# CONTROL_MODULE register map
Vendor: Texas Instruments
Peripheral module from a debugger description file (folder am437x).
Registers are 32-bit, access per field, no defined reset value unless marked. A register's access mark holds for its fields unless they carry their own. Offsets are as the file gives them; lines under a group give offsets from that group; [hi:lo] are bit positions; {n}, {i} and the like mark numbered series; 'fields as' and 'values as' point back to an identical list; <NAME> marks a mode.

## CONTROL_MODULE (part 1 of 5)
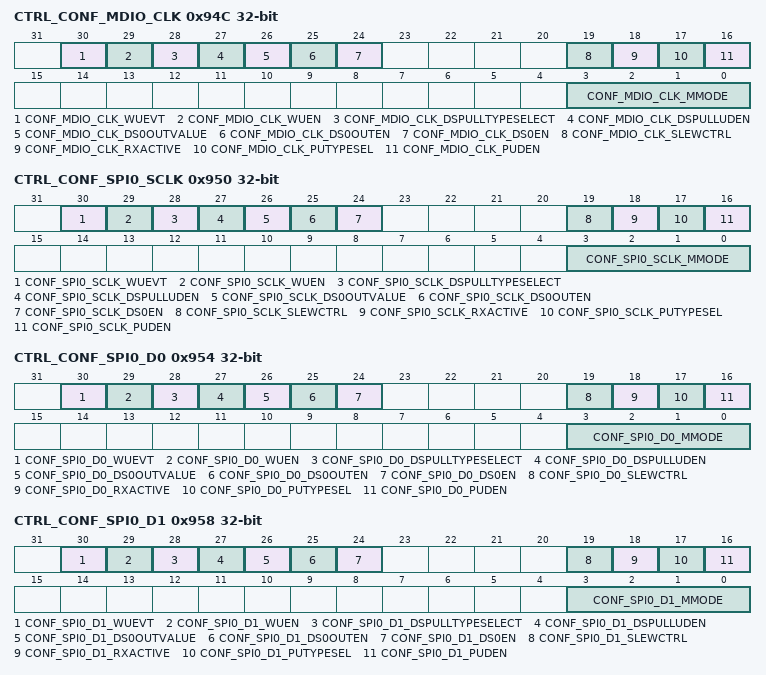
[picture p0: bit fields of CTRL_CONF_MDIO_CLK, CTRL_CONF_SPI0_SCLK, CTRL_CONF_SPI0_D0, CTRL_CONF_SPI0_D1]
0x94C CTRL_CONF_MDIO_CLK
  [30] CONF_MDIO_CLK_WUEVT ro — Wakeup Event [[br]]0 = No event [[br]]1 = Event occurred
  [29] CONF_MDIO_CLK_WUEN rw — Wakeup enable [[br]]0 = disable [[br]]1 = enable
  [28] CONF_MDIO_CLK_DSPULLTYPESELECT rw — DS0 mode Pull-Up/Down selection [[br]]0 = Offmode Pull-Down selected [[br]]1 = Offmode Pull-Up selected
  [27] CONF_MDIO_CLK_DSPULLUDEN rw — DS0 mode Pull-Up/Down enable. [[br]]This is an active low signal. [[br]]1 = Pullup / Pulldown disabled [[br]]0 = Pullup / Pulldown enabled
  [26] CONF_MDIO_CLK_DS0OUTVALUE rw — DS0 mode output value [[br]]0 = Set value at 0 [[br]]1 = Set value at 1
  [25] CONF_MDIO_CLK_DS0OUTEN rw — DS0 mode output enable This is an active low signal [[br]]0 = Output Enable [[br]]1 = Output Disable
  [24] CONF_MDIO_CLK_DS0EN rw — DS0 mode override control [[br]]0: IO state keeps its previous state when DS0 mode is active [[br]]1: IO state is forced to OFF mode value when DS0 mode is active
  [19] CONF_MDIO_CLK_SLEWCTRL rw — Select between Faster or Slower Slew rate [[br]]0 = fast [[br]]1 = slow
  [18] CONF_MDIO_CLK_RXACTIVE rw — Input Enable Value for the PAD [[br]]0 = receiver disabled [[br]]1 = receiver enabled
  [17] CONF_MDIO_CLK_PUTYPESEL rw — Pad Pullup / Pulldown Type Selection [[br]]0 = Pulldown selected [[br]]1 = Pullup selected
  [16] CONF_MDIO_CLK_PUDEN rw — Pad Pullup / Pulldown Enable. [[br]]This is an active low signal [[br]]1 = Pullup / Pulldown disabled [[br]]0 = Pullup / Pulldown enabled
  [3:0] CONF_MDIO_CLK_MMODE rw — Pad Functional Signal Mux Select
0x950 CTRL_CONF_SPI0_SCLK
  [30] CONF_SPI0_SCLK_WUEVT ro — Wakeup Event [[br]]0 = No event [[br]]1 = Event occurred
  [29] CONF_SPI0_SCLK_WUEN rw — Wakeup enable [[br]]0 = disable [[br]]1 = enable
  [28] CONF_SPI0_SCLK_DSPULLTYPESELECT rw — DS0 mode Pull-Up/Down selection [[br]]0 = Offmode Pull-Down selected [[br]]1 = Offmode Pull-Up selected
  [27] CONF_SPI0_SCLK_DSPULLUDEN rw — DS0 mode Pull-Up/Down enable. [[br]]This is an active low signal. [[br]]1 = Pullup / Pulldown disabled [[br]]0 = Pullup / Pulldown enabled
  [26] CONF_SPI0_SCLK_DS0OUTVALUE rw — DS0 mode output value [[br]]0 = Set value at 0 [[br]]1 = Set value at 1
  [25] CONF_SPI0_SCLK_DS0OUTEN rw — DS0 mode output enable This is an active low signal [[br]]0 = Output Enable [[br]]1 = Output Disable
  [24] CONF_SPI0_SCLK_DS0EN rw — DS0 mode override control [[br]]0: IO state keeps its previous state when DS0 mode is active [[br]]1: IO state is forced to OFF mode value when DS0 mode is active
  [19] CONF_SPI0_SCLK_SLEWCTRL rw — Select between Faster or Slower Slew rate [[br]]0 = fast [[br]]1 = slow
  [18] CONF_SPI0_SCLK_RXACTIVE rw — Input Enable Value for the PAD [[br]]0 = receiver disabled [[br]]1 = receiver enabled
  [17] CONF_SPI0_SCLK_PUTYPESEL rw — Pad Pullup / Pulldown Type Selection [[br]]0 = Pulldown selected [[br]]1 = Pullup selected
  [16] CONF_SPI0_SCLK_PUDEN rw — Pad Pullup / Pulldown Enable. [[br]]This is an active low signal [[br]]1 = Pullup / Pulldown disabled [[br]]0 = Pullup / Pulldown enabled
  [3:0] CONF_SPI0_SCLK_MMODE rw — Pad Functional Signal Mux Select
0x954 CTRL_CONF_SPI0_D0
  [30] CONF_SPI0_D0_WUEVT ro — Wakeup Event [[br]]0 = No event [[br]]1 = Event occurred
  [29] CONF_SPI0_D0_WUEN rw — Wakeup enable [[br]]0 = disable [[br]]1 = enable
  [28] CONF_SPI0_D0_DSPULLTYPESELECT rw — DS0 mode Pull-Up/Down selection [[br]]0 = Offmode Pull-Down selected [[br]]1 = Offmode Pull-Up selected
  [27] CONF_SPI0_D0_DSPULLUDEN rw — DS0 mode Pull-Up/Down enable. [[br]]This is an active low signal. [[br]]1 = Pullup / Pulldown disabled [[br]]0 = Pullup / Pulldown enabled
  [26] CONF_SPI0_D0_DS0OUTVALUE rw — DS0 mode output value [[br]]0 = Set value at 0 [[br]]1 = Set value at 1
  [25] CONF_SPI0_D0_DS0OUTEN rw — DS0 mode output enable This is an active low signal [[br]]0 = Output Enable [[br]]1 = Output Disable
  [24] CONF_SPI0_D0_DS0EN rw — DS0 mode override control [[br]]0: IO state keeps its previous state when DS0 mode is active [[br]]1: IO state is forced to OFF mode value when DS0 mode is active
  [19] CONF_SPI0_D0_SLEWCTRL rw — Select between Faster or Slower Slew rate [[br]]0 = fast [[br]]1 = slow
  [18] CONF_SPI0_D0_RXACTIVE rw — Input Enable Value for the PAD [[br]]0 = receiver disabled [[br]]1 = receiver enabled
  [17] CONF_SPI0_D0_PUTYPESEL rw — Pad Pullup / Pulldown Type Selection [[br]]0 = Pulldown selected [[br]]1 = Pullup selected
  [16] CONF_SPI0_D0_PUDEN rw — Pad Pullup / Pulldown Enable. [[br]]This is an active low signal [[br]]1 = Pullup / Pulldown disabled [[br]]0 = Pullup / Pulldown enabled
  [3:0] CONF_SPI0_D0_MMODE rw — Pad Functional Signal Mux Select
0x958 CTRL_CONF_SPI0_D1
  [30] CONF_SPI0_D1_WUEVT ro — Wakeup Event [[br]]0 = No event [[br]]1 = Event occurred
  [29] CONF_SPI0_D1_WUEN rw — Wakeup enable [[br]]0 = disable [[br]]1 = enable
  [28] CONF_SPI0_D1_DSPULLTYPESELECT rw — DS0 mode Pull-Up/Down selection [[br]]0 = Offmode Pull-Down selected [[br]]1 = Offmode Pull-Up selected
  [27] CONF_SPI0_D1_DSPULLUDEN rw — DS0 mode Pull-Up/Down enable. [[br]]This is an active low signal. [[br]]1 = Pullup / Pulldown disabled [[br]]0 = Pullup / Pulldown enabled
  [26] CONF_SPI0_D1_DS0OUTVALUE rw — DS0 mode output value [[br]]0 = Set value at 0 [[br]]1 = Set value at 1
  [25] CONF_SPI0_D1_DS0OUTEN rw — DS0 mode output enable This is an active low signal [[br]]0 = Output Enable [[br]]1 = Output Disable
  [24] CONF_SPI0_D1_DS0EN rw — DS0 mode override control [[br]]0: IO state keeps its previous state when DS0 mode is active [[br]]1: IO state is forced to OFF mode value when DS0 mode is active
  [19] CONF_SPI0_D1_SLEWCTRL rw — Select between Faster or Slower Slew rate [[br]]0 = fast [[br]]1 = slow
  [18] CONF_SPI0_D1_RXACTIVE rw — Input Enable Value for the PAD [[br]]0 = receiver disabled [[br]]1 = receiver enabled
  [17] CONF_SPI0_D1_PUTYPESEL rw — Pad Pullup / Pulldown Type Selection [[br]]0 = Pulldown selected [[br]]1 = Pullup selected
  [16] CONF_SPI0_D1_PUDEN rw — Pad Pullup / Pulldown Enable. [[br]]This is an active low signal [[br]]1 = Pullup / Pulldown disabled [[br]]0 = Pullup / Pulldown enabled
  [3:0] CONF_SPI0_D1_MMODE rw — Pad Functional Signal Mux Select
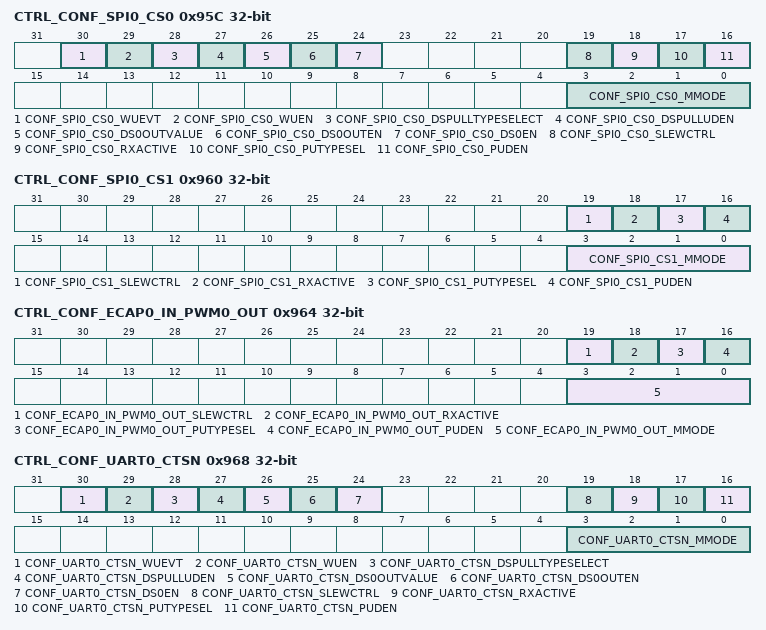
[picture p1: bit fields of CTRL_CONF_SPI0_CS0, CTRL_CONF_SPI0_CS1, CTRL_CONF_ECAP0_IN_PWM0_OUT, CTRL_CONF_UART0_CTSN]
0x95C CTRL_CONF_SPI0_CS0
  [30] CONF_SPI0_CS0_WUEVT ro — Wakeup Event [[br]]0 = No event [[br]]1 = Event occurred
  [29] CONF_SPI0_CS0_WUEN rw — Wakeup enable [[br]]0 = disable [[br]]1 = enable
  [28] CONF_SPI0_CS0_DSPULLTYPESELECT rw — DS0 mode Pull-Up/Down selection [[br]]0 = Offmode Pull-Down selected [[br]]1 = Offmode Pull-Up selected
  [27] CONF_SPI0_CS0_DSPULLUDEN rw — DS0 mode Pull-Up/Down enable. [[br]]This is an active low signal. [[br]]1 = Pullup / Pulldown disabled [[br]]0 = Pullup / Pulldown enabled
  [26] CONF_SPI0_CS0_DS0OUTVALUE rw — DS0 mode output value [[br]]0 = Set value at 0 [[br]]1 = Set value at 1
  [25] CONF_SPI0_CS0_DS0OUTEN rw — DS0 mode output enable This is an active low signal [[br]]0 = Output Enable [[br]]1 = Output Disable
  [24] CONF_SPI0_CS0_DS0EN rw — DS0 mode override control [[br]]0: IO state keeps its previous state when DS0 mode is active [[br]]1: IO state is forced to OFF mode value when DS0 mode is active
  [19] CONF_SPI0_CS0_SLEWCTRL rw — Select between Faster or Slower Slew rate [[br]]0 = fast [[br]]1 = slow
  [18] CONF_SPI0_CS0_RXACTIVE rw — Input Enable Value for the PAD [[br]]0 = receiver disabled [[br]]1 = receiver enabled
  [17] CONF_SPI0_CS0_PUTYPESEL rw — Pad Pullup / Pulldown Type Selection [[br]]0 = Pulldown selected [[br]]1 = Pullup selected
  [16] CONF_SPI0_CS0_PUDEN rw — Pad Pullup / Pulldown Enable. [[br]]This is an active low signal [[br]]1 = Pullup / Pulldown disabled [[br]]0 = Pullup / Pulldown enabled
  [3:0] CONF_SPI0_CS0_MMODE rw — Pad Functional Signal Mux Select
0x960 CTRL_CONF_SPI0_CS1
  [19] CONF_SPI0_CS1_SLEWCTRL rw — Select between Faster or Slower Slew rate [[br]]0 = fast [[br]]1 = slow
  [18] CONF_SPI0_CS1_RXACTIVE rw — Input Enable Value for the PAD [[br]]0 = receiver disabled [[br]]1 = receiver enabled
  [17] CONF_SPI0_CS1_PUTYPESEL rw — Pad Pullup / Pulldown Type Selection [[br]]0 = Pulldown selected [[br]]1 = Pullup selected
  [16] CONF_SPI0_CS1_PUDEN rw — Pad Pullup / Pulldown Enable. [[br]]This is an active low signal [[br]]1 = Pullup / Pulldown disabled [[br]]0 = Pullup / Pulldown enabled
  [3:0] CONF_SPI0_CS1_MMODE rw — Pad Functional Signal Mux Select
0x964 CTRL_CONF_ECAP0_IN_PWM0_OUT
  [19] CONF_ECAP0_IN_PWM0_OUT_SLEWCTRL rw — Select between Faster or Slower Slew rate [[br]]0 = fast [[br]]1 = slow
  [18] CONF_ECAP0_IN_PWM0_OUT_RXACTIVE rw — Input Enable Value for the PAD [[br]]0 = receiver disabled [[br]]1 = receiver enabled
  [17] CONF_ECAP0_IN_PWM0_OUT_PUTYPESEL rw — Pad Pullup / Pulldown Type Selection [[br]]0 = Pulldown selected [[br]]1 = Pullup selected
  [16] CONF_ECAP0_IN_PWM0_OUT_PUDEN rw — Pad Pullup / Pulldown Enable. [[br]]This is an active low signal [[br]]1 = Pullup / Pulldown disabled [[br]]0 = Pullup / Pulldown enabled
  [3:0] CONF_ECAP0_IN_PWM0_OUT_MMODE rw — Pad Functional Signal Mux Select
0x968 CTRL_CONF_UART0_CTSN
  [30] CONF_UART0_CTSN_WUEVT ro — Wakeup Event [[br]]0 = No event [[br]]1 = Event occurred
  [29] CONF_UART0_CTSN_WUEN rw — Wakeup enable [[br]]0 = disable [[br]]1 = enable
  [28] CONF_UART0_CTSN_DSPULLTYPESELECT rw — DS0 mode Pull-Up/Down selection [[br]]0 = Offmode Pull-Down selected [[br]]1 = Offmode Pull-Up selected
  [27] CONF_UART0_CTSN_DSPULLUDEN rw — DS0 mode Pull-Up/Down enable. [[br]]This is an active low signal. [[br]]1 = Pullup / Pulldown disabled [[br]]0 = Pullup / Pulldown enabled
  [26] CONF_UART0_CTSN_DS0OUTVALUE rw — DS0 mode output value [[br]]0 = Set value at 0 [[br]]1 = Set value at 1
  [25] CONF_UART0_CTSN_DS0OUTEN rw — DS0 mode output enable This is an active low signal [[br]]0 = Output Enable [[br]]1 = Output Disable
  [24] CONF_UART0_CTSN_DS0EN rw — DS0 mode override control [[br]]0: IO state keeps its previous state when DS0 mode is active [[br]]1: IO state is forced to OFF mode value when DS0 mode is active
  [19] CONF_UART0_CTSN_SLEWCTRL rw — Select between Faster or Slower Slew rate [[br]]0 = fast [[br]]1 = slow
  [18] CONF_UART0_CTSN_RXACTIVE rw — Input Enable Value for the PAD [[br]]0 = receiver disabled [[br]]1 = receiver enabled
  [17] CONF_UART0_CTSN_PUTYPESEL rw — Pad Pullup / Pulldown Type Selection [[br]]0 = Pulldown selected [[br]]1 = Pullup selected
  [16] CONF_UART0_CTSN_PUDEN rw — Pad Pullup / Pulldown Enable. [[br]]This is an active low signal [[br]]1 = Pullup / Pulldown disabled [[br]]0 = Pullup / Pulldown enabled
  [3:0] CONF_UART0_CTSN_MMODE rw — Pad Functional Signal Mux Select
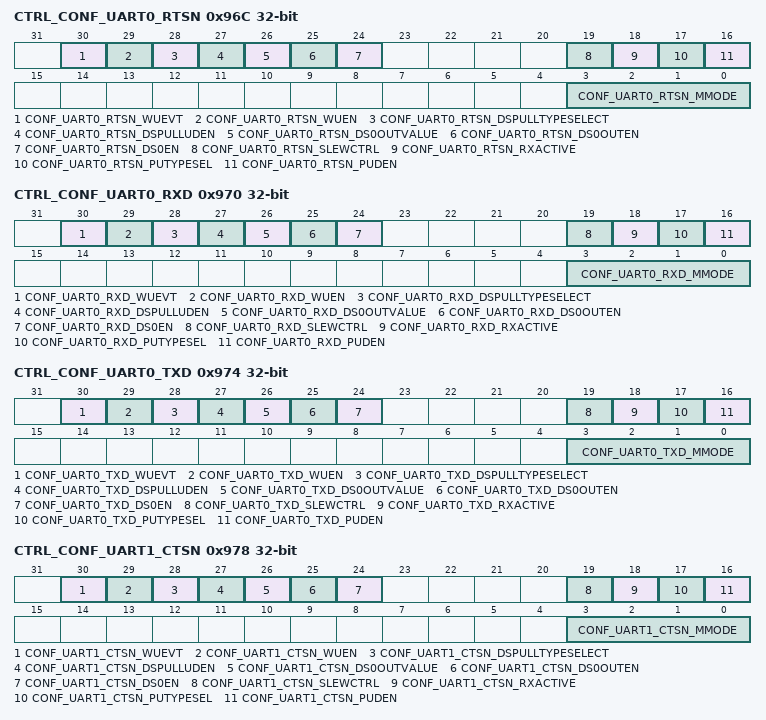
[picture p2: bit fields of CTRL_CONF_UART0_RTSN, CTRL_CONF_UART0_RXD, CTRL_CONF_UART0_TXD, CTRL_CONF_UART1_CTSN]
0x96C CTRL_CONF_UART0_RTSN
  [30] CONF_UART0_RTSN_WUEVT ro — Wakeup Event [[br]]0 = No event [[br]]1 = Event occurred
  [29] CONF_UART0_RTSN_WUEN rw — Wakeup enable [[br]]0 = disable [[br]]1 = enable
  [28] CONF_UART0_RTSN_DSPULLTYPESELECT rw — DS0 mode Pull-Up/Down selection [[br]]0 = Offmode Pull-Down selected [[br]]1 = Offmode Pull-Up selected
  [27] CONF_UART0_RTSN_DSPULLUDEN rw — DS0 mode Pull-Up/Down enable. [[br]]This is an active low signal. [[br]]1 = Pullup / Pulldown disabled [[br]]0 = Pullup / Pulldown enabled
  [26] CONF_UART0_RTSN_DS0OUTVALUE rw — DS0 mode output value [[br]]0 = Set value at 0 [[br]]1 = Set value at 1
  [25] CONF_UART0_RTSN_DS0OUTEN rw — DS0 mode output enable This is an active low signal [[br]]0 = Output Enable [[br]]1 = Output Disable
  [24] CONF_UART0_RTSN_DS0EN rw — DS0 mode override control [[br]]0: IO state keeps its previous state when DS0 mode is active [[br]]1: IO state is forced to OFF mode value when DS0 mode is active
  [19] CONF_UART0_RTSN_SLEWCTRL rw — Select between Faster or Slower Slew rate [[br]]0 = fast [[br]]1 = slow
  [18] CONF_UART0_RTSN_RXACTIVE rw — Input Enable Value for the PAD [[br]]0 = receiver disabled [[br]]1 = receiver enabled
  [17] CONF_UART0_RTSN_PUTYPESEL rw — Pad Pullup / Pulldown Type Selection [[br]]0 = Pulldown selected [[br]]1 = Pullup selected
  [16] CONF_UART0_RTSN_PUDEN rw — Pad Pullup / Pulldown Enable. [[br]]This is an active low signal [[br]]1 = Pullup / Pulldown disabled [[br]]0 = Pullup / Pulldown enabled
  [3:0] CONF_UART0_RTSN_MMODE rw — Pad Functional Signal Mux Select
0x970 CTRL_CONF_UART0_RXD
  [30] CONF_UART0_RXD_WUEVT ro — Wakeup Event [[br]]0 = No event [[br]]1 = Event occurred
  [29] CONF_UART0_RXD_WUEN rw — Wakeup enable [[br]]0 = disable [[br]]1 = enable
  [28] CONF_UART0_RXD_DSPULLTYPESELECT rw — DS0 mode Pull-Up/Down selection [[br]]0 = Offmode Pull-Down selected [[br]]1 = Offmode Pull-Up selected
  [27] CONF_UART0_RXD_DSPULLUDEN rw — DS0 mode Pull-Up/Down enable. [[br]]This is an active low signal. [[br]]1 = Pullup / Pulldown disabled [[br]]0 = Pullup / Pulldown enabled
  [26] CONF_UART0_RXD_DS0OUTVALUE rw — DS0 mode output value [[br]]0 = Set value at 0 [[br]]1 = Set value at 1
  [25] CONF_UART0_RXD_DS0OUTEN rw — DS0 mode output enable This is an active low signal [[br]]0 = Output Enable [[br]]1 = Output Disable
  [24] CONF_UART0_RXD_DS0EN rw — DS0 mode override control [[br]]0: IO state keeps its previous state when DS0 mode is active [[br]]1: IO state is forced to OFF mode value when DS0 mode is active
  [19] CONF_UART0_RXD_SLEWCTRL rw — Select between Faster or Slower Slew rate [[br]]0 = fast [[br]]1 = slow
  [18] CONF_UART0_RXD_RXACTIVE rw — Input Enable Value for the PAD [[br]]0 = receiver disabled [[br]]1 = receiver enabled
  [17] CONF_UART0_RXD_PUTYPESEL rw — Pad Pullup / Pulldown Type Selection [[br]]0 = Pulldown selected [[br]]1 = Pullup selected
  [16] CONF_UART0_RXD_PUDEN rw — Pad Pullup / Pulldown Enable. [[br]]This is an active low signal [[br]]1 = Pullup / Pulldown disabled [[br]]0 = Pullup / Pulldown enabled
  [3:0] CONF_UART0_RXD_MMODE rw — Pad Functional Signal Mux Select
0x974 CTRL_CONF_UART0_TXD
  [30] CONF_UART0_TXD_WUEVT ro — Wakeup Event [[br]]0 = No event [[br]]1 = Event occurred
  [29] CONF_UART0_TXD_WUEN rw — Wakeup enable [[br]]0 = disable [[br]]1 = enable
  [28] CONF_UART0_TXD_DSPULLTYPESELECT rw — DS0 mode Pull-Up/Down selection [[br]]0 = Offmode Pull-Down selected [[br]]1 = Offmode Pull-Up selected
  [27] CONF_UART0_TXD_DSPULLUDEN rw — DS0 mode Pull-Up/Down enable. [[br]]This is an active low signal. [[br]]1 = Pullup / Pulldown disabled [[br]]0 = Pullup / Pulldown enabled
  [26] CONF_UART0_TXD_DS0OUTVALUE rw — DS0 mode output value [[br]]0 = Set value at 0 [[br]]1 = Set value at 1
  [25] CONF_UART0_TXD_DS0OUTEN rw — DS0 mode output enable This is an active low signal [[br]]0 = Output Enable [[br]]1 = Output Disable
  [24] CONF_UART0_TXD_DS0EN rw — DS0 mode override control [[br]]0: IO state keeps its previous state when DS0 mode is active [[br]]1: IO state is forced to OFF mode value when DS0 mode is active
  [19] CONF_UART0_TXD_SLEWCTRL rw — Select between Faster or Slower Slew rate [[br]]0 = fast [[br]]1 = slow
  [18] CONF_UART0_TXD_RXACTIVE rw — Input Enable Value for the PAD [[br]]0 = receiver disabled [[br]]1 = receiver enabled
  [17] CONF_UART0_TXD_PUTYPESEL rw — Pad Pullup / Pulldown Type Selection [[br]]0 = Pulldown selected [[br]]1 = Pullup selected
  [16] CONF_UART0_TXD_PUDEN rw — Pad Pullup / Pulldown Enable. [[br]]This is an active low signal [[br]]1 = Pullup / Pulldown disabled [[br]]0 = Pullup / Pulldown enabled
  [3:0] CONF_UART0_TXD_MMODE rw — Pad Functional Signal Mux Select
0x978 CTRL_CONF_UART1_CTSN
  [30] CONF_UART1_CTSN_WUEVT ro — Wakeup Event [[br]]0 = No event [[br]]1 = Event occurred
  [29] CONF_UART1_CTSN_WUEN rw — Wakeup enable [[br]]0 = disable [[br]]1 = enable
  [28] CONF_UART1_CTSN_DSPULLTYPESELECT rw — DS0 mode Pull-Up/Down selection [[br]]0 = Offmode Pull-Down selected [[br]]1 = Offmode Pull-Up selected
  [27] CONF_UART1_CTSN_DSPULLUDEN rw — DS0 mode Pull-Up/Down enable. [[br]]This is an active low signal. [[br]]1 = Pullup / Pulldown disabled [[br]]0 = Pullup / Pulldown enabled
  [26] CONF_UART1_CTSN_DS0OUTVALUE rw — DS0 mode output value [[br]]0 = Set value at 0 [[br]]1 = Set value at 1
  [25] CONF_UART1_CTSN_DS0OUTEN rw — DS0 mode output enable This is an active low signal [[br]]0 = Output Enable [[br]]1 = Output Disable
  [24] CONF_UART1_CTSN_DS0EN rw — DS0 mode override control [[br]]0: IO state keeps its previous state when DS0 mode is active [[br]]1: IO state is forced to OFF mode value when DS0 mode is active
  [19] CONF_UART1_CTSN_SLEWCTRL rw — Select between Faster or Slower Slew rate [[br]]0 = fast [[br]]1 = slow
  [18] CONF_UART1_CTSN_RXACTIVE rw — Input Enable Value for the PAD [[br]]0 = receiver disabled [[br]]1 = receiver enabled
  [17] CONF_UART1_CTSN_PUTYPESEL rw — Pad Pullup / Pulldown Type Selection [[br]]0 = Pulldown selected [[br]]1 = Pullup selected
  [16] CONF_UART1_CTSN_PUDEN rw — Pad Pullup / Pulldown Enable. [[br]]This is an active low signal [[br]]1 = Pullup / Pulldown disabled [[br]]0 = Pullup / Pulldown enabled
  [3:0] CONF_UART1_CTSN_MMODE rw — Pad Functional Signal Mux Select
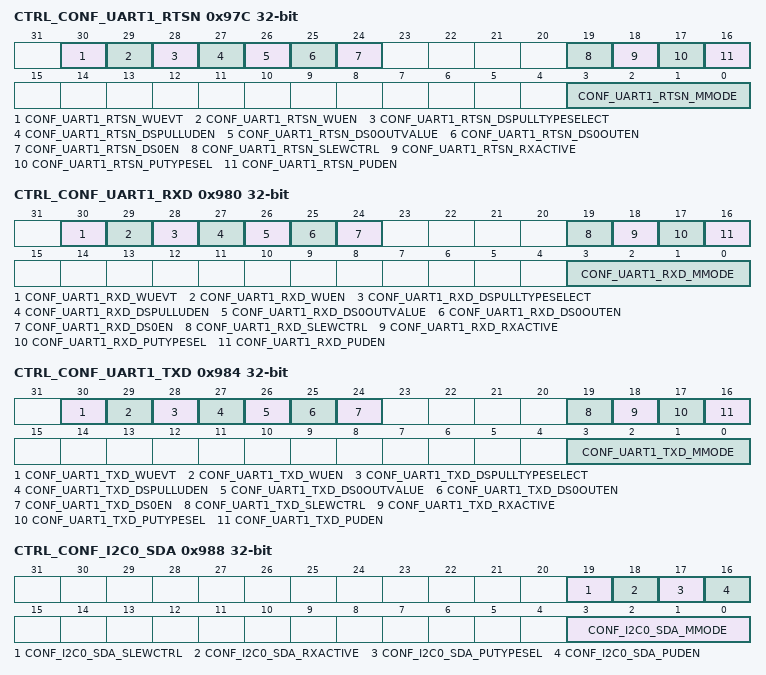
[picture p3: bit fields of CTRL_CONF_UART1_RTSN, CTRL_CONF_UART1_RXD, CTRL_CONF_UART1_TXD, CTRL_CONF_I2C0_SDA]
0x97C CTRL_CONF_UART1_RTSN
  [30] CONF_UART1_RTSN_WUEVT ro — Wakeup Event [[br]]0 = No event [[br]]1 = Event occurred
  [29] CONF_UART1_RTSN_WUEN rw — Wakeup enable [[br]]0 = disable [[br]]1 = enable
  [28] CONF_UART1_RTSN_DSPULLTYPESELECT rw — DS0 mode Pull-Up/Down selection [[br]]0 = Offmode Pull-Down selected [[br]]1 = Offmode Pull-Up selected
  [27] CONF_UART1_RTSN_DSPULLUDEN rw — DS0 mode Pull-Up/Down enable. [[br]]This is an active low signal. [[br]]1 = Pullup / Pulldown disabled [[br]]0 = Pullup / Pulldown enabled
  [26] CONF_UART1_RTSN_DS0OUTVALUE rw — DS0 mode output value [[br]]0 = Set value at 0 [[br]]1 = Set value at 1
  [25] CONF_UART1_RTSN_DS0OUTEN rw — DS0 mode output enable This is an active low signal [[br]]0 = Output Enable [[br]]1 = Output Disable
  [24] CONF_UART1_RTSN_DS0EN rw — DS0 mode override control [[br]]0: IO state keeps its previous state when DS0 mode is active [[br]]1: IO state is forced to OFF mode value when DS0 mode is active
  [19] CONF_UART1_RTSN_SLEWCTRL rw — Select between Faster or Slower Slew rate [[br]]0 = fast [[br]]1 = slow
  [18] CONF_UART1_RTSN_RXACTIVE rw — Input Enable Value for the PAD [[br]]0 = receiver disabled [[br]]1 = receiver enabled
  [17] CONF_UART1_RTSN_PUTYPESEL rw — Pad Pullup / Pulldown Type Selection [[br]]0 = Pulldown selected [[br]]1 = Pullup selected
  [16] CONF_UART1_RTSN_PUDEN rw — Pad Pullup / Pulldown Enable. [[br]]This is an active low signal [[br]]1 = Pullup / Pulldown disabled [[br]]0 = Pullup / Pulldown enabled
  [3:0] CONF_UART1_RTSN_MMODE rw — Pad Functional Signal Mux Select
0x980 CTRL_CONF_UART1_RXD
  [30] CONF_UART1_RXD_WUEVT ro — Wakeup Event [[br]]0 = No event [[br]]1 = Event occurred
  [29] CONF_UART1_RXD_WUEN rw — Wakeup enable [[br]]0 = disable [[br]]1 = enable
  [28] CONF_UART1_RXD_DSPULLTYPESELECT rw — DS0 mode Pull-Up/Down selection [[br]]0 = Offmode Pull-Down selected [[br]]1 = Offmode Pull-Up selected
  [27] CONF_UART1_RXD_DSPULLUDEN rw — DS0 mode Pull-Up/Down enable. [[br]]This is an active low signal. [[br]]1 = Pullup / Pulldown disabled [[br]]0 = Pullup / Pulldown enabled
  [26] CONF_UART1_RXD_DS0OUTVALUE rw — DS0 mode output value [[br]]0 = Set value at 0 [[br]]1 = Set value at 1
  [25] CONF_UART1_RXD_DS0OUTEN rw — DS0 mode output enable This is an active low signal [[br]]0 = Output Enable [[br]]1 = Output Disable
  [24] CONF_UART1_RXD_DS0EN rw — DS0 mode override control [[br]]0: IO state keeps its previous state when DS0 mode is active [[br]]1: IO state is forced to OFF mode value when DS0 mode is active
  [19] CONF_UART1_RXD_SLEWCTRL rw — Select between Faster or Slower Slew rate [[br]]0 = fast [[br]]1 = slow
  [18] CONF_UART1_RXD_RXACTIVE rw — Input Enable Value for the PAD [[br]]0 = receiver disabled [[br]]1 = receiver enabled
  [17] CONF_UART1_RXD_PUTYPESEL rw — Pad Pullup / Pulldown Type Selection [[br]]0 = Pulldown selected [[br]]1 = Pullup selected
  [16] CONF_UART1_RXD_PUDEN rw — Pad Pullup / Pulldown Enable. [[br]]This is an active low signal [[br]]1 = Pullup / Pulldown disabled [[br]]0 = Pullup / Pulldown enabled
  [3:0] CONF_UART1_RXD_MMODE rw — Pad Functional Signal Mux Select
0x984 CTRL_CONF_UART1_TXD
  [30] CONF_UART1_TXD_WUEVT ro — Wakeup Event [[br]]0 = No event [[br]]1 = Event occurred
  [29] CONF_UART1_TXD_WUEN rw — Wakeup enable [[br]]0 = disable [[br]]1 = enable
  [28] CONF_UART1_TXD_DSPULLTYPESELECT rw — DS0 mode Pull-Up/Down selection [[br]]0 = Offmode Pull-Down selected [[br]]1 = Offmode Pull-Up selected
  [27] CONF_UART1_TXD_DSPULLUDEN rw — DS0 mode Pull-Up/Down enable. [[br]]This is an active low signal. [[br]]1 = Pullup / Pulldown disabled [[br]]0 = Pullup / Pulldown enabled
  [26] CONF_UART1_TXD_DS0OUTVALUE rw — DS0 mode output value [[br]]0 = Set value at 0 [[br]]1 = Set value at 1
  [25] CONF_UART1_TXD_DS0OUTEN rw — DS0 mode output enable This is an active low signal [[br]]0 = Output Enable [[br]]1 = Output Disable
  [24] CONF_UART1_TXD_DS0EN rw — DS0 mode override control [[br]]0: IO state keeps its previous state when DS0 mode is active [[br]]1: IO state is forced to OFF mode value when DS0 mode is active
  [19] CONF_UART1_TXD_SLEWCTRL rw — Select between Faster or Slower Slew rate [[br]]0 = fast [[br]]1 = slow
  [18] CONF_UART1_TXD_RXACTIVE rw — Input Enable Value for the PAD [[br]]0 = receiver disabled [[br]]1 = receiver enabled
  [17] CONF_UART1_TXD_PUTYPESEL rw — Pad Pullup / Pulldown Type Selection [[br]]0 = Pulldown selected [[br]]1 = Pullup selected
  [16] CONF_UART1_TXD_PUDEN rw — Pad Pullup / Pulldown Enable. [[br]]This is an active low signal [[br]]1 = Pullup / Pulldown disabled [[br]]0 = Pullup / Pulldown enabled
  [3:0] CONF_UART1_TXD_MMODE rw — Pad Functional Signal Mux Select
0x988 CTRL_CONF_I2C0_SDA
  [19] CONF_I2C0_SDA_SLEWCTRL rw — Select between Faster or Slower Slew rate [[br]]0 = fast [[br]]1 = slow
  [18] CONF_I2C0_SDA_RXACTIVE rw — Input Enable Value for the PAD [[br]]0 = receiver disabled [[br]]1 = receiver enabled
  [17] CONF_I2C0_SDA_PUTYPESEL rw — Pad Pullup / Pulldown Type Selection [[br]]0 = Pulldown selected [[br]]1 = Pullup selected
  [16] CONF_I2C0_SDA_PUDEN rw — Pad Pullup / Pulldown Enable. [[br]]This is an active low signal [[br]]1 = Pullup / Pulldown disabled [[br]]0 = Pullup / Pulldown enabled
  [3:0] CONF_I2C0_SDA_MMODE rw — Pad Functional Signal Mux Select
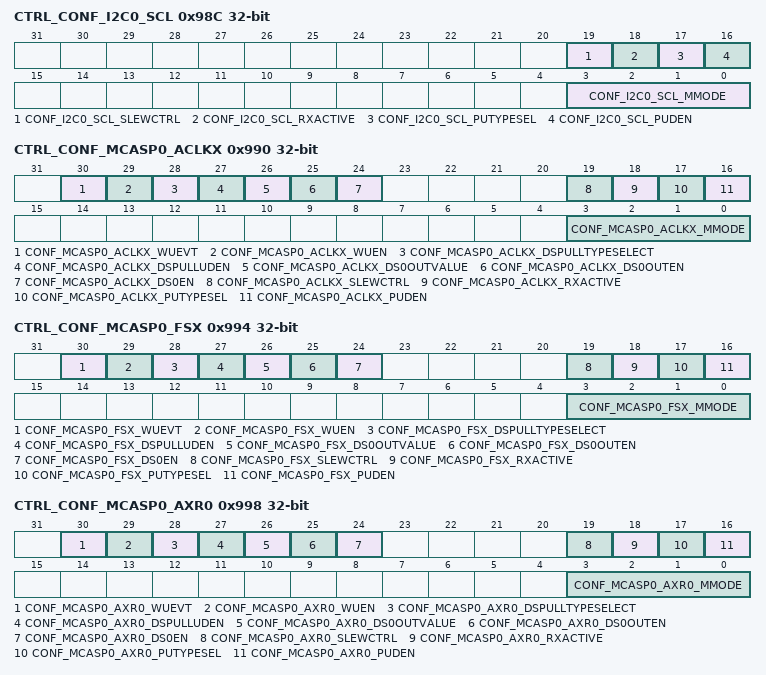
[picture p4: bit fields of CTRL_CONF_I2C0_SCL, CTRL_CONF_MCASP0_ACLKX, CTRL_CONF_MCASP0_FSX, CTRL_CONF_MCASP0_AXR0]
0x98C CTRL_CONF_I2C0_SCL
  [19] CONF_I2C0_SCL_SLEWCTRL rw — Select between Faster or Slower Slew rate [[br]]0 = fast [[br]]1 = slow
  [18] CONF_I2C0_SCL_RXACTIVE rw — Input Enable Value for the PAD [[br]]0 = receiver disabled [[br]]1 = receiver enabled
  [17] CONF_I2C0_SCL_PUTYPESEL rw — Pad Pullup / Pulldown Type Selection [[br]]0 = Pulldown selected [[br]]1 = Pullup selected
  [16] CONF_I2C0_SCL_PUDEN rw — Pad Pullup / Pulldown Enable. [[br]]This is an active low signal [[br]]1 = Pullup / Pulldown disabled [[br]]0 = Pullup / Pulldown enabled
  [3:0] CONF_I2C0_SCL_MMODE rw — Pad Functional Signal Mux Select
0x990 CTRL_CONF_MCASP0_ACLKX
  [30] CONF_MCASP0_ACLKX_WUEVT ro — Wakeup Event [[br]]0 = No event [[br]]1 = Event occurred
  [29] CONF_MCASP0_ACLKX_WUEN rw — Wakeup enable [[br]]0 = disable [[br]]1 = enable
  [28] CONF_MCASP0_ACLKX_DSPULLTYPESELECT rw — DS0 mode Pull-Up/Down selection [[br]]0 = Offmode Pull-Down selected [[br]]1 = Offmode Pull-Up selected
  [27] CONF_MCASP0_ACLKX_DSPULLUDEN rw — DS0 mode Pull-Up/Down enable. [[br]]This is an active low signal. [[br]]1 = Pullup / Pulldown disabled [[br]]0 = Pullup / Pulldown enabled
  [26] CONF_MCASP0_ACLKX_DS0OUTVALUE rw — DS0 mode output value [[br]]0 = Set value at 0 [[br]]1 = Set value at 1
  [25] CONF_MCASP0_ACLKX_DS0OUTEN rw — DS0 mode output enable This is an active low signal [[br]]0 = Output Enable [[br]]1 = Output Disable
  [24] CONF_MCASP0_ACLKX_DS0EN rw — DS0 mode override control [[br]]0: IO state keeps its previous state when DS0 mode is active [[br]]1: IO state is forced to OFF mode value when DS0 mode is active
  [19] CONF_MCASP0_ACLKX_SLEWCTRL rw — Select between Faster or Slower Slew rate [[br]]0 = fast [[br]]1 = slow
  [18] CONF_MCASP0_ACLKX_RXACTIVE rw — Input Enable Value for the PAD [[br]]0 = receiver disabled [[br]]1 = receiver enabled
  [17] CONF_MCASP0_ACLKX_PUTYPESEL rw — Pad Pullup / Pulldown Type Selection [[br]]0 = Pulldown selected [[br]]1 = Pullup selected
  [16] CONF_MCASP0_ACLKX_PUDEN rw — Pad Pullup / Pulldown Enable. [[br]]This is an active low signal [[br]]1 = Pullup / Pulldown disabled [[br]]0 = Pullup / Pulldown enabled
  [3:0] CONF_MCASP0_ACLKX_MMODE rw — Pad Functional Signal Mux Select
0x994 CTRL_CONF_MCASP0_FSX
  [30] CONF_MCASP0_FSX_WUEVT ro — Wakeup Event [[br]]0 = No event [[br]]1 = Event occurred
  [29] CONF_MCASP0_FSX_WUEN rw — Wakeup enable [[br]]0 = disable [[br]]1 = enable
  [28] CONF_MCASP0_FSX_DSPULLTYPESELECT rw — DS0 mode Pull-Up/Down selection [[br]]0 = Offmode Pull-Down selected [[br]]1 = Offmode Pull-Up selected
  [27] CONF_MCASP0_FSX_DSPULLUDEN rw — DS0 mode Pull-Up/Down enable. [[br]]This is an active low signal. [[br]]1 = Pullup / Pulldown disabled [[br]]0 = Pullup / Pulldown enabled
  [26] CONF_MCASP0_FSX_DS0OUTVALUE rw — DS0 mode output value [[br]]0 = Set value at 0 [[br]]1 = Set value at 1
  [25] CONF_MCASP0_FSX_DS0OUTEN rw — DS0 mode output enable This is an active low signal [[br]]0 = Output Enable [[br]]1 = Output Disable
  [24] CONF_MCASP0_FSX_DS0EN rw — DS0 mode override control [[br]]0: IO state keeps its previous state when DS0 mode is active [[br]]1: IO state is forced to OFF mode value when DS0 mode is active
  [19] CONF_MCASP0_FSX_SLEWCTRL rw — Select between Faster or Slower Slew rate [[br]]0 = fast [[br]]1 = slow
  [18] CONF_MCASP0_FSX_RXACTIVE rw — Input Enable Value for the PAD [[br]]0 = receiver disabled [[br]]1 = receiver enabled
  [17] CONF_MCASP0_FSX_PUTYPESEL rw — Pad Pullup / Pulldown Type Selection [[br]]0 = Pulldown selected [[br]]1 = Pullup selected
  [16] CONF_MCASP0_FSX_PUDEN rw — Pad Pullup / Pulldown Enable. [[br]]This is an active low signal [[br]]1 = Pullup / Pulldown disabled [[br]]0 = Pullup / Pulldown enabled
  [3:0] CONF_MCASP0_FSX_MMODE rw — Pad Functional Signal Mux Select
0x998 CTRL_CONF_MCASP0_AXR0
  [30] CONF_MCASP0_AXR0_WUEVT ro — Wakeup Event [[br]]0 = No event [[br]]1 = Event occurred
  [29] CONF_MCASP0_AXR0_WUEN rw — Wakeup enable [[br]]0 = disable [[br]]1 = enable
  [28] CONF_MCASP0_AXR0_DSPULLTYPESELECT rw — DS0 mode Pull-Up/Down selection [[br]]0 = Offmode Pull-Down selected [[br]]1 = Offmode Pull-Up selected
  [27] CONF_MCASP0_AXR0_DSPULLUDEN rw — DS0 mode Pull-Up/Down enable. [[br]]This is an active low signal. [[br]]1 = Pullup / Pulldown disabled [[br]]0 = Pullup / Pulldown enabled
  [26] CONF_MCASP0_AXR0_DS0OUTVALUE rw — DS0 mode output value [[br]]0 = Set value at 0 [[br]]1 = Set value at 1
  [25] CONF_MCASP0_AXR0_DS0OUTEN rw — DS0 mode output enable This is an active low signal [[br]]0 = Output Enable [[br]]1 = Output Disable
  [24] CONF_MCASP0_AXR0_DS0EN rw — DS0 mode override control [[br]]0: IO state keeps its previous state when DS0 mode is active [[br]]1: IO state is forced to OFF mode value when DS0 mode is active
  [19] CONF_MCASP0_AXR0_SLEWCTRL rw — Select between Faster or Slower Slew rate [[br]]0 = fast [[br]]1 = slow
  [18] CONF_MCASP0_AXR0_RXACTIVE rw — Input Enable Value for the PAD [[br]]0 = receiver disabled [[br]]1 = receiver enabled
  [17] CONF_MCASP0_AXR0_PUTYPESEL rw — Pad Pullup / Pulldown Type Selection [[br]]0 = Pulldown selected [[br]]1 = Pullup selected
  [16] CONF_MCASP0_AXR0_PUDEN rw — Pad Pullup / Pulldown Enable. [[br]]This is an active low signal [[br]]1 = Pullup / Pulldown disabled [[br]]0 = Pullup / Pulldown enabled
  [3:0] CONF_MCASP0_AXR0_MMODE rw — Pad Functional Signal Mux Select
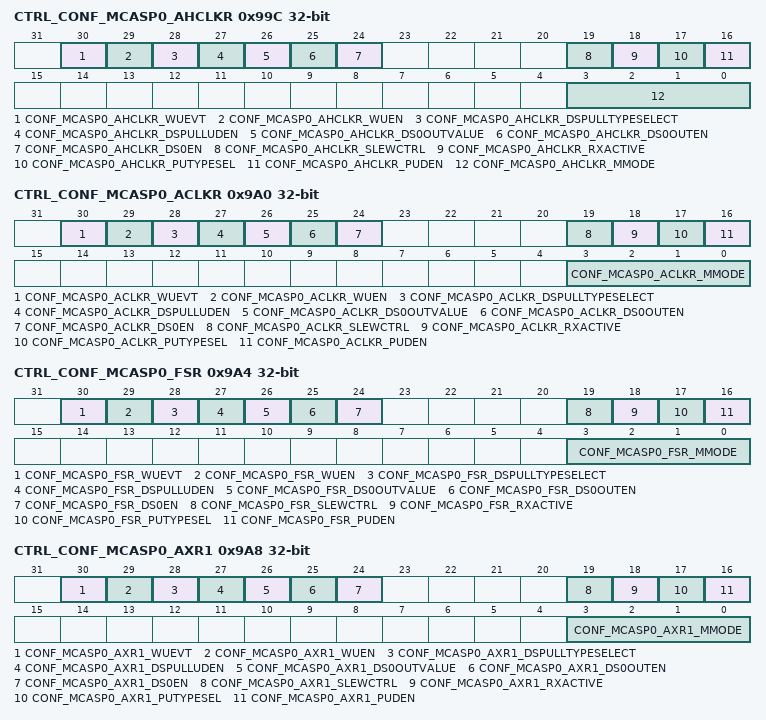
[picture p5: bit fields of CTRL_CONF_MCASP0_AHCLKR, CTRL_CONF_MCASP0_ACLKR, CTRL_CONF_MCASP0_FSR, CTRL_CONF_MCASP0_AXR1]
0x99C CTRL_CONF_MCASP0_AHCLKR
  [30] CONF_MCASP0_AHCLKR_WUEVT ro — Wakeup Event [[br]]0 = No event [[br]]1 = Event occurred
  [29] CONF_MCASP0_AHCLKR_WUEN rw — Wakeup enable [[br]]0 = disable [[br]]1 = enable
  [28] CONF_MCASP0_AHCLKR_DSPULLTYPESELECT rw — DS0 mode Pull-Up/Down selection [[br]]0 = Offmode Pull-Down selected [[br]]1 = Offmode Pull-Up selected
  [27] CONF_MCASP0_AHCLKR_DSPULLUDEN rw — DS0 mode Pull-Up/Down enable. [[br]]This is an active low signal. [[br]]1 = Pullup / Pulldown disabled [[br]]0 = Pullup / Pulldown enabled
  [26] CONF_MCASP0_AHCLKR_DS0OUTVALUE rw — DS0 mode output value [[br]]0 = Set value at 0 [[br]]1 = Set value at 1
  [25] CONF_MCASP0_AHCLKR_DS0OUTEN rw — DS0 mode output enable This is an active low signal [[br]]0 = Output Enable [[br]]1 = Output Disable
  [24] CONF_MCASP0_AHCLKR_DS0EN rw — DS0 mode override control [[br]]0: IO state keeps its previous state when DS0 mode is active [[br]]1: IO state is forced to OFF mode value when DS0 mode is active
  [19] CONF_MCASP0_AHCLKR_SLEWCTRL rw — Select between Faster or Slower Slew rate [[br]]0 = fast [[br]]1 = slow
  [18] CONF_MCASP0_AHCLKR_RXACTIVE rw — Input Enable Value for the PAD [[br]]0 = receiver disabled [[br]]1 = receiver enabled
  [17] CONF_MCASP0_AHCLKR_PUTYPESEL rw — Pad Pullup / Pulldown Type Selection [[br]]0 = Pulldown selected [[br]]1 = Pullup selected
  [16] CONF_MCASP0_AHCLKR_PUDEN rw — Pad Pullup / Pulldown Enable. [[br]]This is an active low signal [[br]]1 = Pullup / Pulldown disabled [[br]]0 = Pullup / Pulldown enabled
  [3:0] CONF_MCASP0_AHCLKR_MMODE rw — Pad Functional Signal Mux Select
0x9A0 CTRL_CONF_MCASP0_ACLKR
  [30] CONF_MCASP0_ACLKR_WUEVT ro — Wakeup Event [[br]]0 = No event [[br]]1 = Event occurred
  [29] CONF_MCASP0_ACLKR_WUEN rw — Wakeup enable [[br]]0 = disable [[br]]1 = enable
  [28] CONF_MCASP0_ACLKR_DSPULLTYPESELECT rw — DS0 mode Pull-Up/Down selection [[br]]0 = Offmode Pull-Down selected [[br]]1 = Offmode Pull-Up selected
  [27] CONF_MCASP0_ACLKR_DSPULLUDEN rw — DS0 mode Pull-Up/Down enable. [[br]]This is an active low signal. [[br]]1 = Pullup / Pulldown disabled [[br]]0 = Pullup / Pulldown enabled
  [26] CONF_MCASP0_ACLKR_DS0OUTVALUE rw — DS0 mode output value [[br]]0 = Set value at 0 [[br]]1 = Set value at 1
  [25] CONF_MCASP0_ACLKR_DS0OUTEN rw — DS0 mode output enable This is an active low signal [[br]]0 = Output Enable [[br]]1 = Output Disable
  [24] CONF_MCASP0_ACLKR_DS0EN rw — DS0 mode override control [[br]]0: IO state keeps its previous state when DS0 mode is active [[br]]1: IO state is forced to OFF mode value when DS0 mode is active
  [19] CONF_MCASP0_ACLKR_SLEWCTRL rw — Select between Faster or Slower Slew rate [[br]]0 = fast [[br]]1 = slow
  [18] CONF_MCASP0_ACLKR_RXACTIVE rw — Input Enable Value for the PAD [[br]]0 = receiver disabled [[br]]1 = receiver enabled
  [17] CONF_MCASP0_ACLKR_PUTYPESEL rw — Pad Pullup / Pulldown Type Selection [[br]]0 = Pulldown selected [[br]]1 = Pullup selected
  [16] CONF_MCASP0_ACLKR_PUDEN rw — Pad Pullup / Pulldown Enable. [[br]]This is an active low signal [[br]]1 = Pullup / Pulldown disabled [[br]]0 = Pullup / Pulldown enabled
  [3:0] CONF_MCASP0_ACLKR_MMODE rw — Pad Functional Signal Mux Select
0x9A4 CTRL_CONF_MCASP0_FSR
  [30] CONF_MCASP0_FSR_WUEVT ro — Wakeup Event [[br]]0 = No event [[br]]1 = Event occurred
  [29] CONF_MCASP0_FSR_WUEN rw — Wakeup enable [[br]]0 = disable [[br]]1 = enable
  [28] CONF_MCASP0_FSR_DSPULLTYPESELECT rw — DS0 mode Pull-Up/Down selection [[br]]0 = Offmode Pull-Down selected [[br]]1 = Offmode Pull-Up selected
  [27] CONF_MCASP0_FSR_DSPULLUDEN rw — DS0 mode Pull-Up/Down enable. [[br]]This is an active low signal. [[br]]1 = Pullup / Pulldown disabled [[br]]0 = Pullup / Pulldown enabled
  [26] CONF_MCASP0_FSR_DS0OUTVALUE rw — DS0 mode output value [[br]]0 = Set value at 0 [[br]]1 = Set value at 1
  [25] CONF_MCASP0_FSR_DS0OUTEN rw — DS0 mode output enable This is an active low signal [[br]]0 = Output Enable [[br]]1 = Output Disable
  [24] CONF_MCASP0_FSR_DS0EN rw — DS0 mode override control [[br]]0: IO state keeps its previous state when DS0 mode is active [[br]]1: IO state is forced to OFF mode value when DS0 mode is active
  [19] CONF_MCASP0_FSR_SLEWCTRL rw — Select between Faster or Slower Slew rate [[br]]0 = fast [[br]]1 = slow
  [18] CONF_MCASP0_FSR_RXACTIVE rw — Input Enable Value for the PAD [[br]]0 = receiver disabled [[br]]1 = receiver enabled
  [17] CONF_MCASP0_FSR_PUTYPESEL rw — Pad Pullup / Pulldown Type Selection [[br]]0 = Pulldown selected [[br]]1 = Pullup selected
  [16] CONF_MCASP0_FSR_PUDEN rw — Pad Pullup / Pulldown Enable. [[br]]This is an active low signal [[br]]1 = Pullup / Pulldown disabled [[br]]0 = Pullup / Pulldown enabled
  [3:0] CONF_MCASP0_FSR_MMODE rw — Pad Functional Signal Mux Select
0x9A8 CTRL_CONF_MCASP0_AXR1
  [30] CONF_MCASP0_AXR1_WUEVT ro — Wakeup Event [[br]]0 = No event [[br]]1 = Event occurred
  [29] CONF_MCASP0_AXR1_WUEN rw — Wakeup enable [[br]]0 = disable [[br]]1 = enable
  [28] CONF_MCASP0_AXR1_DSPULLTYPESELECT rw — DS0 mode Pull-Up/Down selection [[br]]0 = Offmode Pull-Down selected [[br]]1 = Offmode Pull-Up selected
  [27] CONF_MCASP0_AXR1_DSPULLUDEN rw — DS0 mode Pull-Up/Down enable. [[br]]This is an active low signal. [[br]]1 = Pullup / Pulldown disabled [[br]]0 = Pullup / Pulldown enabled
  [26] CONF_MCASP0_AXR1_DS0OUTVALUE rw — DS0 mode output value [[br]]0 = Set value at 0 [[br]]1 = Set value at 1
  [25] CONF_MCASP0_AXR1_DS0OUTEN rw — DS0 mode output enable This is an active low signal [[br]]0 = Output Enable [[br]]1 = Output Disable
  [24] CONF_MCASP0_AXR1_DS0EN rw — DS0 mode override control [[br]]0: IO state keeps its previous state when DS0 mode is active [[br]]1: IO state is forced to OFF mode value when DS0 mode is active
  [19] CONF_MCASP0_AXR1_SLEWCTRL rw — Select between Faster or Slower Slew rate [[br]]0 = fast [[br]]1 = slow
  [18] CONF_MCASP0_AXR1_RXACTIVE rw — Input Enable Value for the PAD [[br]]0 = receiver disabled [[br]]1 = receiver enabled
  [17] CONF_MCASP0_AXR1_PUTYPESEL rw — Pad Pullup / Pulldown Type Selection [[br]]0 = Pulldown selected [[br]]1 = Pullup selected
  [16] CONF_MCASP0_AXR1_PUDEN rw — Pad Pullup / Pulldown Enable. [[br]]This is an active low signal [[br]]1 = Pullup / Pulldown disabled [[br]]0 = Pullup / Pulldown enabled
  [3:0] CONF_MCASP0_AXR1_MMODE rw — Pad Functional Signal Mux Select
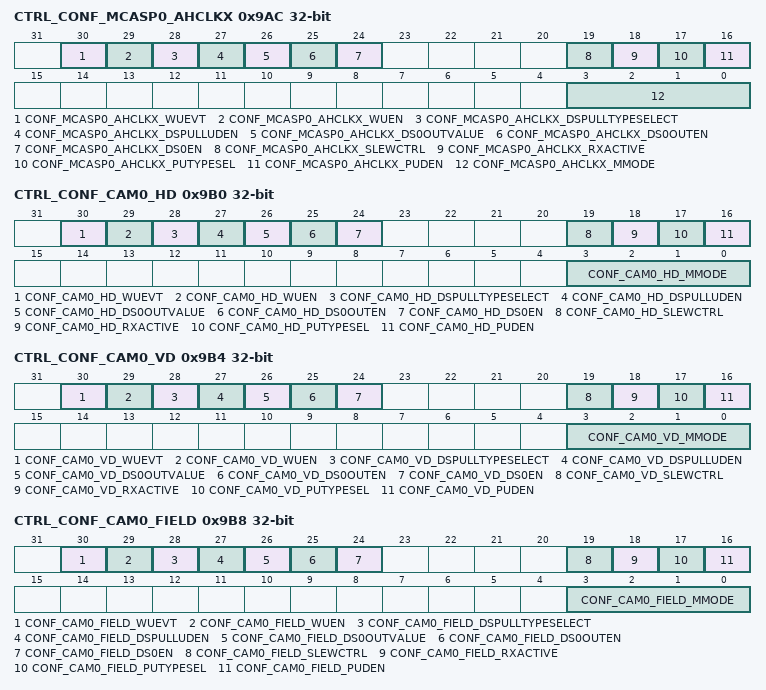
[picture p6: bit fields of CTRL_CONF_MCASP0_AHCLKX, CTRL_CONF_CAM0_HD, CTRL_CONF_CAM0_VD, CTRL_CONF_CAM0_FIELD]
0x9AC CTRL_CONF_MCASP0_AHCLKX
  [30] CONF_MCASP0_AHCLKX_WUEVT ro — Wakeup Event [[br]]0 = No event [[br]]1 = Event occurred
  [29] CONF_MCASP0_AHCLKX_WUEN rw — Wakeup enable [[br]]0 = disable [[br]]1 = enable
  [28] CONF_MCASP0_AHCLKX_DSPULLTYPESELECT rw — DS0 mode Pull-Up/Down selection [[br]]0 = Offmode Pull-Down selected [[br]]1 = Offmode Pull-Up selected
  [27] CONF_MCASP0_AHCLKX_DSPULLUDEN rw — DS0 mode Pull-Up/Down enable. [[br]]This is an active low signal. [[br]]1 = Pullup / Pulldown disabled [[br]]0 = Pullup / Pulldown enabled
  [26] CONF_MCASP0_AHCLKX_DS0OUTVALUE rw — DS0 mode output value [[br]]0 = Set value at 0 [[br]]1 = Set value at 1
  [25] CONF_MCASP0_AHCLKX_DS0OUTEN rw — DS0 mode output enable This is an active low signal [[br]]0 = Output Enable [[br]]1 = Output Disable
  [24] CONF_MCASP0_AHCLKX_DS0EN rw — DS0 mode override control [[br]]0: IO state keeps its previous state when DS0 mode is active [[br]]1: IO state is forced to OFF mode value when DS0 mode is active
  [19] CONF_MCASP0_AHCLKX_SLEWCTRL rw — Select between Faster or Slower Slew rate [[br]]0 = fast [[br]]1 = slow
  [18] CONF_MCASP0_AHCLKX_RXACTIVE rw — Input Enable Value for the PAD [[br]]0 = receiver disabled [[br]]1 = receiver enabled
  [17] CONF_MCASP0_AHCLKX_PUTYPESEL rw — Pad Pullup / Pulldown Type Selection [[br]]0 = Pulldown selected [[br]]1 = Pullup selected
  [16] CONF_MCASP0_AHCLKX_PUDEN rw — Pad Pullup / Pulldown Enable. [[br]]This is an active low signal [[br]]1 = Pullup / Pulldown disabled [[br]]0 = Pullup / Pulldown enabled
  [3:0] CONF_MCASP0_AHCLKX_MMODE rw — Pad Functional Signal Mux Select
0x9B0 CTRL_CONF_CAM0_HD
  [30] CONF_CAM0_HD_WUEVT ro — Wakeup Event [[br]]0 = No event [[br]]1 = Event occurred
  [29] CONF_CAM0_HD_WUEN rw — Wakeup enable [[br]]0 = disable [[br]]1 = enable
  [28] CONF_CAM0_HD_DSPULLTYPESELECT rw — DS0 mode Pull-Up/Down selection [[br]]0 = Offmode Pull-Down selected [[br]]1 = Offmode Pull-Up selected
  [27] CONF_CAM0_HD_DSPULLUDEN rw — DS0 mode Pull-Up/Down enable. [[br]]This is an active low signal. [[br]]1 = Pullup / Pulldown disabled [[br]]0 = Pullup / Pulldown enabled
  [26] CONF_CAM0_HD_DS0OUTVALUE rw — DS0 mode output value [[br]]0 = Set value at 0 [[br]]1 = Set value at 1
  [25] CONF_CAM0_HD_DS0OUTEN rw — DS0 mode output enable This is an active low signal [[br]]0 = Output Enable [[br]]1 = Output Disable
  [24] CONF_CAM0_HD_DS0EN rw — DS0 mode override control [[br]]0: IO state keeps its previous state when DS0 mode is active [[br]]1: IO state is forced to OFF mode value when DS0 mode is active
  [19] CONF_CAM0_HD_SLEWCTRL rw — Select between Faster or Slower Slew rate [[br]]0 = fast [[br]]1 = slow
  [18] CONF_CAM0_HD_RXACTIVE rw — Input Enable Value for the PAD [[br]]0 = receiver disabled [[br]]1 = receiver enabled
  [17] CONF_CAM0_HD_PUTYPESEL rw — Pad Pullup / Pulldown Type Selection [[br]]0 = Pulldown selected [[br]]1 = Pullup selected
  [16] CONF_CAM0_HD_PUDEN rw — Pad Pullup / Pulldown Enable. [[br]]This is an active low signal [[br]]1 = Pullup / Pulldown disabled [[br]]0 = Pullup / Pulldown enabled
  [3:0] CONF_CAM0_HD_MMODE rw — Pad Functional Signal Mux Select
0x9B4 CTRL_CONF_CAM0_VD
  [30] CONF_CAM0_VD_WUEVT ro — Wakeup Event [[br]]0 = No event [[br]]1 = Event occurred
  [29] CONF_CAM0_VD_WUEN rw — Wakeup enable [[br]]0 = disable [[br]]1 = enable
  [28] CONF_CAM0_VD_DSPULLTYPESELECT rw — DS0 mode Pull-Up/Down selection [[br]]0 = Offmode Pull-Down selected [[br]]1 = Offmode Pull-Up selected
  [27] CONF_CAM0_VD_DSPULLUDEN rw — DS0 mode Pull-Up/Down enable. [[br]]This is an active low signal. [[br]]1 = Pullup / Pulldown disabled [[br]]0 = Pullup / Pulldown enabled
  [26] CONF_CAM0_VD_DS0OUTVALUE rw — DS0 mode output value [[br]]0 = Set value at 0 [[br]]1 = Set value at 1
  [25] CONF_CAM0_VD_DS0OUTEN rw — DS0 mode output enable This is an active low signal [[br]]0 = Output Enable [[br]]1 = Output Disable
  [24] CONF_CAM0_VD_DS0EN rw — DS0 mode override control [[br]]0: IO state keeps its previous state when DS0 mode is active [[br]]1: IO state is forced to OFF mode value when DS0 mode is active
  [19] CONF_CAM0_VD_SLEWCTRL rw — Select between Faster or Slower Slew rate [[br]]0 = fast [[br]]1 = slow
  [18] CONF_CAM0_VD_RXACTIVE rw — Input Enable Value for the PAD [[br]]0 = receiver disabled [[br]]1 = receiver enabled
  [17] CONF_CAM0_VD_PUTYPESEL rw — Pad Pullup / Pulldown Type Selection [[br]]0 = Pulldown selected [[br]]1 = Pullup selected
  [16] CONF_CAM0_VD_PUDEN rw — Pad Pullup / Pulldown Enable. [[br]]This is an active low signal [[br]]1 = Pullup / Pulldown disabled [[br]]0 = Pullup / Pulldown enabled
  [3:0] CONF_CAM0_VD_MMODE rw — Pad Functional Signal Mux Select
0x9B8 CTRL_CONF_CAM0_FIELD
  [30] CONF_CAM0_FIELD_WUEVT ro — Wakeup Event [[br]]0 = No event [[br]]1 = Event occurred
  [29] CONF_CAM0_FIELD_WUEN rw — Wakeup enable [[br]]0 = disable [[br]]1 = enable
  [28] CONF_CAM0_FIELD_DSPULLTYPESELECT rw — DS0 mode Pull-Up/Down selection [[br]]0 = Offmode Pull-Down selected [[br]]1 = Offmode Pull-Up selected
  [27] CONF_CAM0_FIELD_DSPULLUDEN rw — DS0 mode Pull-Up/Down enable. [[br]]This is an active low signal. [[br]]1 = Pullup / Pulldown disabled [[br]]0 = Pullup / Pulldown enabled
  [26] CONF_CAM0_FIELD_DS0OUTVALUE rw — DS0 mode output value [[br]]0 = Set value at 0 [[br]]1 = Set value at 1
  [25] CONF_CAM0_FIELD_DS0OUTEN rw — DS0 mode output enable This is an active low signal [[br]]0 = Output Enable [[br]]1 = Output Disable
  [24] CONF_CAM0_FIELD_DS0EN rw — DS0 mode override control [[br]]0: IO state keeps its previous state when DS0 mode is active [[br]]1: IO state is forced to OFF mode value when DS0 mode is active
  [19] CONF_CAM0_FIELD_SLEWCTRL rw — Select between Faster or Slower Slew rate [[br]]0 = fast [[br]]1 = slow
  [18] CONF_CAM0_FIELD_RXACTIVE rw — Input Enable Value for the PAD [[br]]0 = receiver disabled [[br]]1 = receiver enabled
  [17] CONF_CAM0_FIELD_PUTYPESEL rw — Pad Pullup / Pulldown Type Selection [[br]]0 = Pulldown selected [[br]]1 = Pullup selected
  [16] CONF_CAM0_FIELD_PUDEN rw — Pad Pullup / Pulldown Enable. [[br]]This is an active low signal [[br]]1 = Pullup / Pulldown disabled [[br]]0 = Pullup / Pulldown enabled
  [3:0] CONF_CAM0_FIELD_MMODE rw — Pad Functional Signal Mux Select
